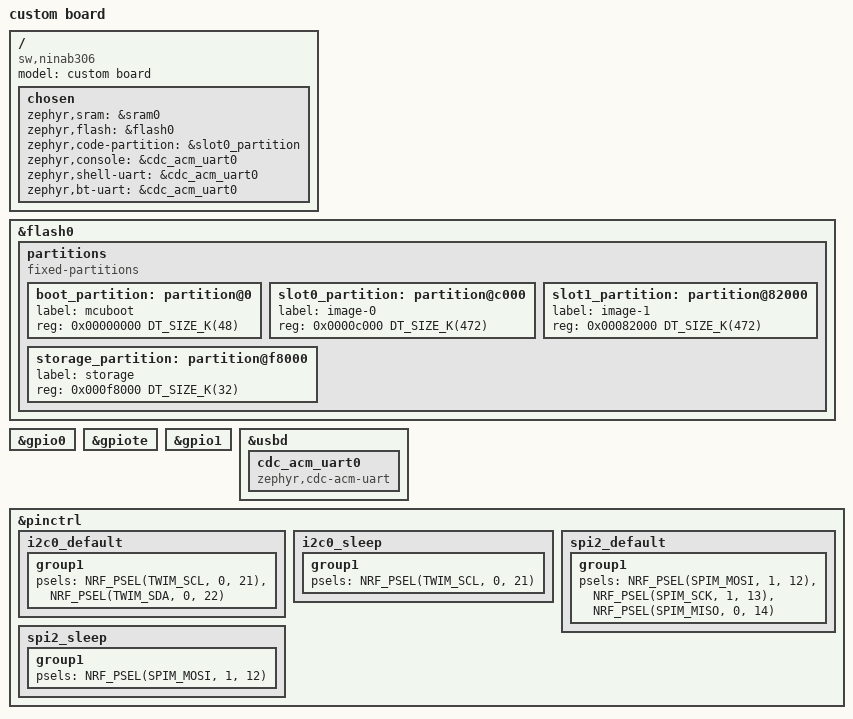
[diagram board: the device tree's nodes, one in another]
/dts-v1/;
#include <nordic/nrf52840_qiaa.dtsi>
#include "ninab306-pinctrl.dtsi"

/ {
	model = "custom board";
	compatible = "sw,ninab306";

	chosen {
		zephyr,sram = &sram0;
		zephyr,flash = &flash0;
		zephyr,code-partition = &slot0_partition;
		zephyr,console = &cdc_acm_uart0;
        zephyr,shell-uart = &cdc_acm_uart0;
        zephyr,bt-uart = &cdc_acm_uart0;
		
	};
};

&flash0 {
	partitions {
		compatible = "fixed-partitions";
		#address-cells = <1>;
		#size-cells = <1>;

		boot_partition: partition@0 {
			label = "mcuboot";
			reg = <0x00000000 DT_SIZE_K(48)>;
		};

		slot0_partition: partition@c000 {
			label = "image-0";
			reg = <0x0000c000 DT_SIZE_K(472)>;
		};

		slot1_partition: partition@82000 {
			label = "image-1";
			reg = <0x00082000 DT_SIZE_K(472)>;
		};

		storage_partition: partition@f8000 {
			label = "storage";
			reg = <0x000f8000 DT_SIZE_K(32)>;
		};
	};
};

&gpio0 {
	status = "okay";
};

&gpiote {
	status = "okay";
};

&gpio1 {
	status = "okay";
};

&usbd {
	status = "okay";
	 cdc_acm_uart0: cdc_acm_uart0 {
        compatible = "zephyr,cdc-acm-uart";
	 };
};

&pinctrl {
	i2c0_default: i2c0_default {
		group1 {
			psels = <NRF_PSEL(TWIM_SCL, 0, 21)>, <NRF_PSEL(TWIM_SDA, 0, 22)>;
		};
	};

	i2c0_sleep: i2c0_sleep {
		group1 {
			psels = <NRF_PSEL(TWIM_SCL, 0, 21)>;
		};
	};

	spi2_default: spi2_default {
		group1 {
			psels = <NRF_PSEL(SPIM_MOSI, 1, 12)>,
					<NRF_PSEL(SPIM_SCK, 1, 13)>,
					<NRF_PSEL(SPIM_MISO, 0, 14)>;
		};
	};

	spi2_sleep: spi2_sleep {
		group1 {
			psels = <NRF_PSEL(SPIM_MOSI, 1, 12)>;
		};
	};
};
